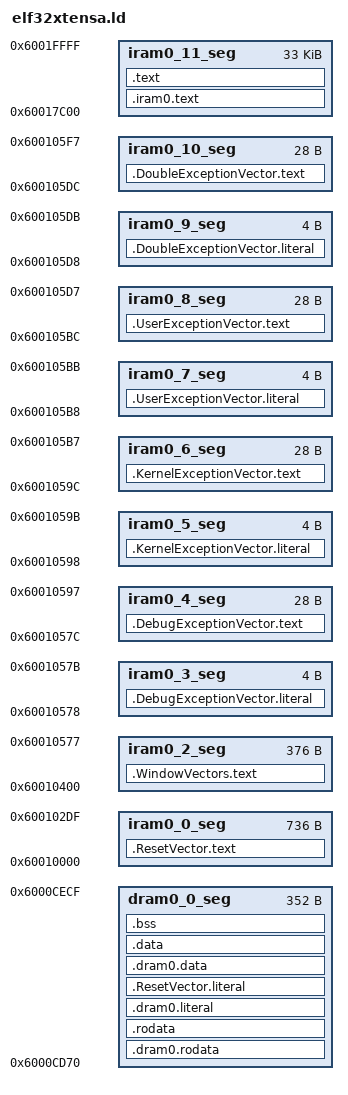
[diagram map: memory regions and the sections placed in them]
/* This linker script generated from xt-genldscripts.tpp for LSP min-rt */
/* Linker Script for default link */
MEMORY
{
  dram0_0_seg :                           org = 0x6000CD70, len = 0x160
  iram0_0_seg :                           org = 0x60010000, len = 0x2E0
  iram0_2_seg :                           org = 0x60010400, len = 0x178
  iram0_3_seg :                           org = 0x60010578, len = 0x4
  iram0_4_seg :                           org = 0x6001057C, len = 0x1C
  iram0_5_seg :                           org = 0x60010598, len = 0x4
  iram0_6_seg :                           org = 0x6001059C, len = 0x1C
  iram0_7_seg :                           org = 0x600105B8, len = 0x4
  iram0_8_seg :                           org = 0x600105BC, len = 0x1C
  iram0_9_seg :                           org = 0x600105D8, len = 0x4
  iram0_10_seg :                          org = 0x600105DC, len = 0x1C
  iram0_11_seg :                          org = 0x60017C00, len = 0x8400
}

PHDRS
{
  dram0_0_phdr PT_LOAD;
  dram0_0_bss_phdr PT_LOAD;
  iram0_0_phdr PT_LOAD;
  iram0_1_phdr PT_LOAD;
  iram0_2_phdr PT_LOAD;
  iram0_3_phdr PT_LOAD;
  iram0_4_phdr PT_LOAD;
  iram0_5_phdr PT_LOAD;
  iram0_6_phdr PT_LOAD;
  iram0_7_phdr PT_LOAD;
  iram0_8_phdr PT_LOAD;
  iram0_9_phdr PT_LOAD;
  iram0_10_phdr PT_LOAD;
  iram0_11_phdr PT_LOAD;
}


/*  Default entry point:  */
ENTRY(_ResetVector)
_rom_store_table = 0;
PROVIDE(_memmap_vecbase_reset = 0x60010400);
/* Various memory-map dependent cache attribute settings: */
_memmap_cacheattr_wb_base = 0x00021000;
_memmap_cacheattr_wt_base = 0x00021000;
_memmap_cacheattr_bp_base = 0x00022000;
_memmap_cacheattr_unused_mask = 0xFFF00FFF;
_memmap_cacheattr_wb_trapnull = 0x2222122F;
_memmap_cacheattr_wba_trapnull = 0x2222122F;
_memmap_cacheattr_wbna_trapnull = 0x2222122F;
_memmap_cacheattr_wt_trapnull = 0x2222122F;
_memmap_cacheattr_bp_trapnull = 0x2222222F;
_memmap_cacheattr_wb_strict = 0xFFF21FFF;
_memmap_cacheattr_wt_strict = 0xFFF21FFF;
_memmap_cacheattr_bp_strict = 0xFFF22FFF;
_memmap_cacheattr_wb_allvalid = 0x22221222;
_memmap_cacheattr_wt_allvalid = 0x22221222;
_memmap_cacheattr_bp_allvalid = 0x22222222;
PROVIDE(_memmap_cacheattr_reset = _memmap_cacheattr_wb_trapnull);

SECTIONS
{

  .dram0.rodata : ALIGN(4)
  {
    _dram0_rodata_start = ABSOLUTE(.);
    *(.dram0.rodata)
    *(.dram.rodata)
    _dram0_rodata_end = ABSOLUTE(.);
  } >dram0_0_seg :dram0_0_phdr

  .rodata : ALIGN(4)
  {
    _rodata_start = ABSOLUTE(.);
    *(.rodata)
    *(.rodata.*)
    *(.gnu.linkonce.r.*)
    *(.rodata1)
    __XT_EXCEPTION_TABLE__ = ABSOLUTE(.);
    KEEP (*(.xt_except_table))
    KEEP (*(.gcc_except_table))
    *(.gnu.linkonce.e.*)
    *(.gnu.version_r)
    KEEP (*(.eh_frame))
    /*  C++ constructor and destructor tables, properly ordered:  */
    KEEP (*crtbegin.o(.ctors))
    KEEP (*(EXCLUDE_FILE (*crtend.o) .ctors))
    KEEP (*(SORT(.ctors.*)))
    KEEP (*(.ctors))
    KEEP (*crtbegin.o(.dtors))
    KEEP (*(EXCLUDE_FILE (*crtend.o) .dtors))
    KEEP (*(SORT(.dtors.*)))
    KEEP (*(.dtors))
    /*  C++ exception handlers table:  */
    __XT_EXCEPTION_DESCS__ = ABSOLUTE(.);
    *(.xt_except_desc)
    *(.gnu.linkonce.h.*)
    __XT_EXCEPTION_DESCS_END__ = ABSOLUTE(.);
    *(.xt_except_desc_end)
    *(.dynamic)
    *(.gnu.version_d)
    . = ALIGN(4);        /* this table MUST be 4-byte aligned */
    _bss_table_start = ABSOLUTE(.);
    LONG(_bss_start)
    LONG(_bss_end)
    _bss_table_end = ABSOLUTE(.);
    _rodata_end = ABSOLUTE(.);
  } >dram0_0_seg :dram0_0_phdr

  .dram0.literal : ALIGN(4)
  {
    _dram0_literal_start = ABSOLUTE(.);
    *(.dram0.literal)
    *(.dram.literal)
    _dram0_literal_end = ABSOLUTE(.);
  } >dram0_0_seg :dram0_0_phdr

  .ResetVector.literal : ALIGN(4)
  {
    _ResetVector_literal_start = ABSOLUTE(.);
    *(.ResetVector.literal)
    _ResetVector_literal_end = ABSOLUTE(.);
  } >dram0_0_seg :dram0_0_phdr

  .dram0.data : ALIGN(4)
  {
    _dram0_data_start = ABSOLUTE(.);
    *(.dram0.data)
    *(.dram.data)
    _dram0_data_end = ABSOLUTE(.);
  } >dram0_0_seg :dram0_0_phdr

  .data : ALIGN(4)
  {
    _data_start = ABSOLUTE(.);
    *(.data)
    *(.data.*)
    *(.gnu.linkonce.d.*)
    KEEP(*(.gnu.linkonce.d.*personality*))
    *(.data1)
    *(.sdata)
    *(.sdata.*)
    *(.gnu.linkonce.s.*)
    *(.sdata2)
    *(.sdata2.*)
    *(.gnu.linkonce.s2.*)
    KEEP(*(.jcr))
    _data_end = ABSOLUTE(.);
  } >dram0_0_seg :dram0_0_phdr

  .bss (NOLOAD) : ALIGN(8)
  {
    . = ALIGN (8);
    _bss_start = ABSOLUTE(.);
    *(.dynsbss)
    *(.sbss)
    *(.sbss.*)
    *(.gnu.linkonce.sb.*)
    *(.scommon)
    *(.sbss2)
    *(.sbss2.*)
    *(.gnu.linkonce.sb2.*)
    *(.dynbss)
    *(.bss)
    *(.bss.*)
    *(.gnu.linkonce.b.*)
    *(COMMON)
    *(.dram0.bss)
    . = ALIGN (8);
    _bss_end = ABSOLUTE(.);
    _end = ALIGN(0x8);
    PROVIDE(end = ALIGN(0x8));
    _stack_sentry = ALIGN(0x8);
  } >dram0_0_seg :dram0_0_bss_phdr
 __stack = 0x60010000;
  _heap_sentry = 0x60010000;

  .ResetVector.text : ALIGN(4)
  {
    _ResetVector_text_start = ABSOLUTE(.);
    KEEP (*(.ResetVector.text))
    _ResetVector_text_end = ABSOLUTE(.);
  } >iram0_0_seg :iram0_0_phdr

  .WindowVectors.text : ALIGN(4)
  {
    _WindowVectors_text_start = ABSOLUTE(.);
    KEEP (*(.WindowVectors.text))
    _WindowVectors_text_end = ABSOLUTE(.);
  } >iram0_2_seg :iram0_2_phdr

  .DebugExceptionVector.literal : ALIGN(4)
  {
    _DebugExceptionVector_literal_start = ABSOLUTE(.);
    *(.DebugExceptionVector.literal)
    _DebugExceptionVector_literal_end = ABSOLUTE(.);
  } >iram0_3_seg :iram0_3_phdr

  .DebugExceptionVector.text : ALIGN(4)
  {
    _DebugExceptionVector_text_start = ABSOLUTE(.);
    KEEP (*(.DebugExceptionVector.text))
    _DebugExceptionVector_text_end = ABSOLUTE(.);
  } >iram0_4_seg :iram0_4_phdr

  .KernelExceptionVector.literal : ALIGN(4)
  {
    _KernelExceptionVector_literal_start = ABSOLUTE(.);
    *(.KernelExceptionVector.literal)
    _KernelExceptionVector_literal_end = ABSOLUTE(.);
  } >iram0_5_seg :iram0_5_phdr

  .KernelExceptionVector.text : ALIGN(4)
  {
    _KernelExceptionVector_text_start = ABSOLUTE(.);
    KEEP (*(.KernelExceptionVector.text))
    _KernelExceptionVector_text_end = ABSOLUTE(.);
  } >iram0_6_seg :iram0_6_phdr

  .UserExceptionVector.literal : ALIGN(4)
  {
    _UserExceptionVector_literal_start = ABSOLUTE(.);
    *(.UserExceptionVector.literal)
    _UserExceptionVector_literal_end = ABSOLUTE(.);
  } >iram0_7_seg :iram0_7_phdr

  .UserExceptionVector.text : ALIGN(4)
  {
    _UserExceptionVector_text_start = ABSOLUTE(.);
    KEEP (*(.UserExceptionVector.text))
    _UserExceptionVector_text_end = ABSOLUTE(.);
  } >iram0_8_seg :iram0_8_phdr

  .DoubleExceptionVector.literal : ALIGN(4)
  {
    _DoubleExceptionVector_literal_start = ABSOLUTE(.);
    *(.DoubleExceptionVector.literal)
    _DoubleExceptionVector_literal_end = ABSOLUTE(.);
  } >iram0_9_seg :iram0_9_phdr

  .DoubleExceptionVector.text : ALIGN(4)
  {
    _DoubleExceptionVector_text_start = ABSOLUTE(.);
    KEEP (*(.DoubleExceptionVector.text))
    _DoubleExceptionVector_text_end = ABSOLUTE(.);
  } >iram0_10_seg :iram0_10_phdr

  .iram0.text : ALIGN(4)
  {
    _iram0_text_start = ABSOLUTE(.);
    *(.iram0.literal .iram.literal .iram.text.literal .iram0.text .iram.text)
    _iram0_text_end = ABSOLUTE(.);
  } >iram0_11_seg :iram0_11_phdr

  .text : ALIGN(4)
  {
    _stext = .;
    _text_start = ABSOLUTE(.);
    *(.entry.text)
    *(.init.literal)
    KEEP(*(.init))
    *(.literal .text .literal.* .text.* .stub .gnu.warning .gnu.linkonce.literal.* .gnu.linkonce.t.*.literal .gnu.linkonce.t.*)
    *(.fini.literal)
    KEEP(*(.fini))
    *(.gnu.version)
    _text_end = ABSOLUTE(.);
    _etext = .;
  } >iram0_11_seg :iram0_11_phdr
  .debug  0 :  { *(.debug) }
  .line  0 :  { *(.line) }
  .debug_srcinfo  0 :  { *(.debug_srcinfo) }
  .debug_sfnames  0 :  { *(.debug_sfnames) }
  .debug_aranges  0 :  { *(.debug_aranges) }
  .debug_pubnames  0 :  { *(.debug_pubnames) }
  .debug_info  0 :  { *(.debug_info) }
  .debug_abbrev  0 :  { *(.debug_abbrev) }
  .debug_line  0 :  { *(.debug_line) }
  .debug_frame  0 :  { *(.debug_frame) }
  .debug_str  0 :  { *(.debug_str) }
  .debug_loc  0 :  { *(.debug_loc) }
  .debug_macinfo  0 :  { *(.debug_macinfo) }
  .debug_weaknames  0 :  { *(.debug_weaknames) }
  .debug_funcnames  0 :  { *(.debug_funcnames) }
  .debug_typenames  0 :  { *(.debug_typenames) }
  .debug_varnames  0 :  { *(.debug_varnames) }
  .xt.insn 0 :
  {
    KEEP (*(.xt.insn))
    KEEP (*(.gnu.linkonce.x.*))
  }
  .xt.prop 0 :
  {
    KEEP (*(.xt.prop))
    KEEP (*(.xt.prop.*))
    KEEP (*(.gnu.linkonce.prop.*))
  }
  .xt.lit 0 :
  {
    KEEP (*(.xt.lit))
    KEEP (*(.xt.lit.*))
    KEEP (*(.gnu.linkonce.p.*))
  }
  .xt.profile_range 0 :
  {
    KEEP (*(.xt.profile_range))
    KEEP (*(.gnu.linkonce.profile_range.*))
  }
  .xt.profile_ranges 0 :
  {
    KEEP (*(.xt.profile_ranges))
    KEEP (*(.gnu.linkonce.xt.profile_ranges.*))
  }
  .xt.profile_files 0 :
  {
    KEEP (*(.xt.profile_files))
    KEEP (*(.gnu.linkonce.xt.profile_files.*))
  }
}

